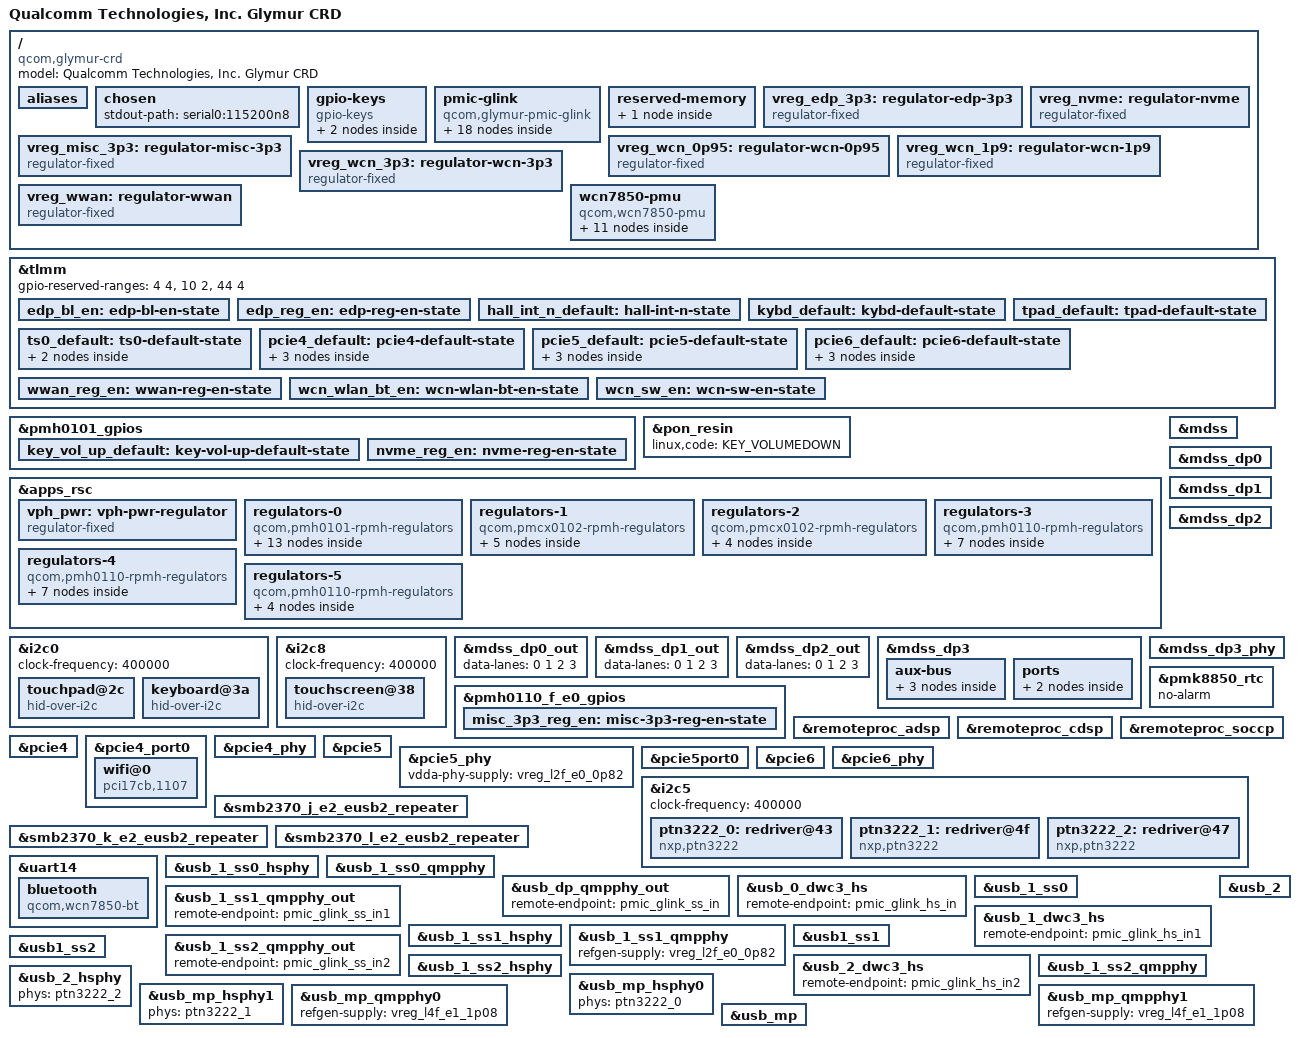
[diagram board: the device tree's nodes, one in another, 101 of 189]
// SPDX-License-Identifier: GPL-2.0-only
/*
 * Copyright (c) Qualcomm Technologies, Inc. and/or its subsidiaries.
 */

/dts-v1/;

#include "glymur.dtsi"
#include "glymur-pmics.dtsi"
#include <dt-bindings/gpio/gpio.h>
#include <dt-bindings/input/gpio-keys.h>
#include <dt-bindings/regulator/qcom,rpmh-regulator.h>
#include <dt-bindings/pinctrl/qcom,pmic-gpio.h>

/ {
	model = "Qualcomm Technologies, Inc. Glymur CRD";
	compatible = "qcom,glymur-crd", "qcom,glymur";

	aliases {
		serial0 = &uart21;
		serial1 = &uart14;
		i2c0 = &i2c16;
		i2c1 = &i2c17;
		i2c2 = &i2c18;
		i2c3 = &i2c19;
		i2c4 = &i2c20;
		i2c5 = &i2c22;
		i2c6 = &i2c23;
		i2c7 = &i2c8;
		i2c8 = &i2c9;
		i2c9 = &i2c10;
		i2c10 = &i2c11;
		i2c11 = &i2c12;
		i2c12 = &i2c13;
		i2c13 = &i2c15;
		i2c14 = &i2c0;
		i2c15 = &i2c1;
		i2c16 = &i2c2;
		i2c17 = &i2c3;
		i2c18 = &i2c4;
		i2c19 = &i2c5;
		i2c20 = &i2c6;
		spi0 = &spi16;
		spi1 = &spi17;
		spi2 = &spi18;
		spi3 = &spi19;
		spi4 = &spi20;
		spi5 = &spi22;
		spi6 = &spi23;
		spi7 = &spi8;
		spi8 = &spi9;
		spi9 = &spi10;
		spi10 = &spi11;
		spi11 = &spi12;
		spi12 = &spi13;
		spi13 = &spi15;
		spi14 = &spi0;
		spi15 = &spi1;
		spi16 = &spi2;
		spi17 = &spi3;
		spi18 = &spi4;
		spi19 = &spi5;
		spi20 = &spi6;
	};

	chosen {
		stdout-path = "serial0:115200n8";
	};

	gpio-keys {
		compatible = "gpio-keys";

		pinctrl-0 = <&key_vol_up_default>, <&hall_int_n_default>;
		pinctrl-names = "default";

		key-volume-up {
			label = "Volume Up";
			linux,code = <KEY_VOLUMEUP>;
			gpios = <&pmh0101_gpios 6 GPIO_ACTIVE_LOW>;
			debounce-interval = <15>;
			linux,can-disable;
			wakeup-source;
		};

		switch-lid {
			gpios = <&tlmm 92 GPIO_ACTIVE_LOW>;
			linux,input-type = <EV_SW>;
			linux,code = <SW_LID>;
			wakeup-source;
			wakeup-event-action = <EV_ACT_DEASSERTED>;
		};
	};

	pmic-glink {
		compatible = "qcom,glymur-pmic-glink";
		#address-cells = <1>;
		#size-cells = <0>;

		connector@0 {
			compatible = "usb-c-connector";
			reg = <0>;

			power-role = "dual";
			data-role = "dual";

			ports {
				#address-cells = <1>;
				#size-cells = <0>;

				port@0 {
					reg = <0>;

					pmic_glink_hs_in: endpoint {
						remote-endpoint = <&usb_0_dwc3_hs>;
					};
				};

				port@1 {
					reg = <1>;

					pmic_glink_ss_in: endpoint {
						remote-endpoint = <&usb_dp_qmpphy_out>;
					};
				};
			};
		};

		connector@1 {
			compatible = "usb-c-connector";
			reg = <1>;
			power-role = "dual";
			data-role = "dual";

			ports {
				#address-cells = <1>;
				#size-cells = <0>;

				port@0 {
					reg = <0>;

					pmic_glink_hs_in1: endpoint {
						remote-endpoint = <&usb_1_dwc3_hs>;
					};
				};

				port@1 {
					reg = <1>;

					pmic_glink_ss_in1: endpoint {
						remote-endpoint = <&usb_1_ss1_qmpphy_out>;
					};
				};
			};
		};

		connector@2 {
			compatible = "usb-c-connector";
			reg = <2>;
			power-role = "dual";
			data-role = "dual";

			ports {
				#address-cells = <1>;
				#size-cells = <0>;

				port@0 {
					reg = <0>;

					pmic_glink_hs_in2: endpoint {
						remote-endpoint = <&usb_2_dwc3_hs>;
					};
				};

				port@1 {
					reg = <1>;

					pmic_glink_ss_in2: endpoint {
						remote-endpoint = <&usb_1_ss2_qmpphy_out>;
					};
				};
			};
		};
	};

	reserved-memory {
		linux,cma {
			compatible = "shared-dma-pool";
			size = <0x0 0x8000000>;
			reusable;
			linux,cma-default;
		};
	};

	vreg_edp_3p3: regulator-edp-3p3 {
		compatible = "regulator-fixed";

		regulator-name = "VREG_EDP_3P3";
		regulator-min-microvolt = <3300000>;
		regulator-max-microvolt = <3300000>;

		gpio = <&tlmm 70 GPIO_ACTIVE_HIGH>;
		enable-active-high;

		pinctrl-0 = <&edp_reg_en>;
		pinctrl-names = "default";

		regulator-boot-on;
	};

	vreg_misc_3p3: regulator-misc-3p3 {
		compatible = "regulator-fixed";

		regulator-name = "VREG_MISC_3P3";
		regulator-min-microvolt = <3300000>;
		regulator-max-microvolt = <3300000>;

		gpio = <&pmh0110_f_e0_gpios 6 GPIO_ACTIVE_HIGH>;
		enable-active-high;

	        pinctrl-names = "default";
	        pinctrl-0 = <&misc_3p3_reg_en>;

		regulator-boot-on;
		regulator-always-on;
	};

	vreg_nvme: regulator-nvme {
		compatible = "regulator-fixed";

		regulator-name = "VREG_NVME_3P3";
		regulator-min-microvolt = <3300000>;
		regulator-max-microvolt = <3300000>;

		gpio = <&pmh0101_gpios 14 GPIO_ACTIVE_HIGH>;
		enable-active-high;

		pinctrl-0 = <&nvme_reg_en>;
		pinctrl-names = "default";
	};

	vreg_wcn_0p95: regulator-wcn-0p95 {
		compatible = "regulator-fixed";

		regulator-name = "VREG_WCN_0P95";
		regulator-min-microvolt = <950000>;
		regulator-max-microvolt = <950000>;

		vin-supply = <&vreg_wcn_3p3>;
	};

	vreg_wcn_1p9: regulator-wcn-1p9 {
		compatible = "regulator-fixed";

		regulator-name = "VREG_WCN_1P9";
		regulator-min-microvolt = <1900000>;
		regulator-max-microvolt = <1900000>;

		vin-supply = <&vreg_wcn_3p3>;
	};

	vreg_wcn_3p3: regulator-wcn-3p3 {
		compatible = "regulator-fixed";

		regulator-name = "VREG_WCN_3P3";
		regulator-min-microvolt = <3300000>;
		regulator-max-microvolt = <3300000>;

		gpio = <&tlmm 214 GPIO_ACTIVE_HIGH>;
		enable-active-high;

		pinctrl-0 = <&wcn_sw_en>;
		pinctrl-names = "default";

		regulator-boot-on;
	};

	vreg_wwan: regulator-wwan {
		compatible = "regulator-fixed";

		regulator-name = "VREG_WWAN_3P3";
		regulator-min-microvolt = <3300000>;
		regulator-max-microvolt = <3300000>;

		gpio = <&tlmm 246 GPIO_ACTIVE_HIGH>;
		enable-active-high;

		pinctrl-names = "default";
		pinctrl-0 = <&wwan_reg_en>;
	};

	wcn7850-pmu {
		compatible = "qcom,wcn7850-pmu";

		vdd-supply = <&vreg_wcn_0p95>;
		vddio-supply = <&vreg_l15b_e0_1p8>;
		vddaon-supply = <&vreg_wcn_0p95>;
		vdddig-supply = <&vreg_wcn_0p95>;
		vddrfa1p2-supply = <&vreg_wcn_1p9>;
		vddrfa1p8-supply = <&vreg_wcn_1p9>;

		wlan-enable-gpios = <&tlmm 117 GPIO_ACTIVE_HIGH>;
		bt-enable-gpios = <&tlmm 116 GPIO_ACTIVE_HIGH>;

		pinctrl-0 = <&wcn_wlan_bt_en>;
		pinctrl-names = "default";

		regulators {
			vreg_pmu_rfa_cmn: ldo0 {
				regulator-name = "vreg_pmu_rfa_cmn";
			};

			vreg_pmu_aon_0p59: ldo1 {
				regulator-name = "vreg_pmu_aon_0p59";
			};

			vreg_pmu_wlcx_0p8: ldo2 {
				regulator-name = "vreg_pmu_wlcx_0p8";
			};

			vreg_pmu_wlmx_0p85: ldo3 {
				regulator-name = "vreg_pmu_wlmx_0p85";
			};

			vreg_pmu_btcmx_0p85: ldo4 {
				regulator-name = "vreg_pmu_btcmx_0p85";
			};

			vreg_pmu_rfa_0p8: ldo5 {
				regulator-name = "vreg_pmu_rfa_0p8";
			};

			vreg_pmu_rfa_1p2: ldo6 {
				regulator-name = "vreg_pmu_rfa_1p2";
			};

			vreg_pmu_rfa_1p8: ldo7 {
				regulator-name = "vreg_pmu_rfa_1p8";
			};

			vreg_pmu_pcie_0p9: ldo8 {
				regulator-name = "vreg_pmu_pcie_0p9";
			};

			vreg_pmu_pcie_1p8: ldo9 {
				regulator-name = "vreg_pmu_pcie_1p8";
			};
		};
	};

};

&tlmm {
	gpio-reserved-ranges = <4 4>, <10 2>, <44 4>; /*Security SPI (TPM)*/

	edp_bl_en: edp-bl-en-state {
		pins = "gpio18";
		function = "gpio";
		drive-strength = <16>;
		bias-disable;
	};

	edp_reg_en: edp-reg-en-state {
		pins = "gpio70";
		function = "gpio";
		drive-strength = <16>;
		bias-disable;
	};

	hall_int_n_default: hall-int-n-state {
		pins = "gpio92";
		function = "gpio";
		bias-disable;
	};

	kybd_default: kybd-default-state {
		pins = "gpio67";
		function = "gpio";
		bias-disable;
	};

	tpad_default: tpad-default-state {
		pins = "gpio3";
		function = "gpio";
		bias-disable;
	};

	ts0_default: ts0-default-state {
		int-n-pins {
			pins = "gpio51";
			function = "gpio";
			bias-disable;
		};

		reset-n-pins {
			pins = "gpio48";
			function = "gpio";
			output-high;
			drive-strength = <16>;
		};
	};

	pcie4_default: pcie4-default-state {
		clkreq-n-pins {
			pins = "gpio147";
			function = "pcie4_clk_req_n";
			drive-strength = <2>;
			bias-pull-up;
		};

		perst-n-pins {
			pins = "gpio146";
			function = "gpio";
			drive-strength = <2>;
			bias-disable;
		};

		wake-n-pins {
			pins = "gpio148";
			function = "gpio";
			drive-strength = <2>;
			bias-pull-up;
		};
	};

	pcie5_default: pcie5-default-state {
		clkreq-n-pins {
			pins = "gpio153";
			function = "pcie5_clk_req_n";
			drive-strength = <2>;
			bias-pull-up;
		};

		perst-n-pins {
			pins = "gpio152";
			function = "gpio";
			drive-strength = <2>;
			bias-disable;
		};

		wake-n-pins {
			pins = "gpio154";
			function = "gpio";
			drive-strength = <2>;
			bias-pull-up;
		};
	};

	pcie6_default: pcie6-default-state {
		clkreq-n-pins {
			pins = "gpio150";
			function = "pcie6_clk_req_n";
			drive-strength = <2>;
			bias-pull-up;
		};

		perst-n-pins {
			pins = "gpio149";
			function = "gpio";
			drive-strength = <2>;
			bias-disable;
		};

		wake-n-pins {
			pins = "gpio151";
			function = "gpio";
			drive-strength = <2>;
			bias-pull-up;
		};
	};

	wwan_reg_en: wwan-reg-en-state {
		pins = "gpio246";
		function = "gpio";
		drive-strength = <2>;
		bias-disable;
	};

	wcn_wlan_bt_en: wcn-wlan-bt-en-state {
		pins = "gpio116", "gpio117";
		function = "gpio";
		drive-strength = <2>;
		bias-disable;
	};

	wcn_sw_en: wcn-sw-en-state {
		pins = "gpio214";
		function = "gpio";
		drive-strength = <2>;
		bias-disable;
	};
};

&pmh0101_gpios {
	key_vol_up_default: key-vol-up-default-state {
		pins = "gpio6";
		function = "gpio";
		output-disable;
		bias-pull-up;
	};
};

&pon_resin {
	linux,code = <KEY_VOLUMEDOWN>;
	status = "okay";
};

&apps_rsc {

	vph_pwr: vph-pwr-regulator {
		compatible = "regulator-fixed";
		regulator-name = "vph_pwr";
		regulator-min-microvolt = <3700000>;
		regulator-max-microvolt = <3700000>;
	};

	regulators-0 {
		compatible = "qcom,pmh0101-rpmh-regulators";
		qcom,pmic-id = "B_E0";

		vdd-bob1-supply = <&vph_pwr>;
		vdd-bob2-supply = <&vph_pwr>;
		vdd-l1-l10-l15-supply = <&vreg_s9f_e0_1p9>;
		vdd-l2-l7-l8-l9-l16-supply = <&vreg_bob1_e0>;
		vdd-l11-l12-l18-supply = <&vreg_s7f_e0_1p32>;
		vdd-l17-supply = <&vreg_bob2_e0>;

		vreg_bob1_e0: bob1 {
			regulator-name = "vreg_bob1_e0";
			regulator-min-microvolt = <2200000>;
			regulator-max-microvolt = <4224000>;
			regulator-initial-mode = <RPMH_REGULATOR_MODE_AUTO>;
		};

		vreg_bob2_e0: bob2 {
			regulator-name = "vreg_bob2_e0";
			regulator-min-microvolt = <2540000>;
			regulator-max-microvolt = <3600000>;
			regulator-initial-mode = <RPMH_REGULATOR_MODE_AUTO>;
		};

		vreg_l1b_e0_1p8: ldo1 {
			regulator-name = "vreg_l1b_e0_1p8";
			regulator-min-microvolt = <1800000>;
			regulator-max-microvolt = <1800000>;
			regulator-initial-mode = <RPMH_REGULATOR_MODE_HPM>;
		};

		vreg_l2b_e0_2p9: ldo2 {
			regulator-name = "vreg_l2b_e0_2p9";
			regulator-min-microvolt = <2900000>;
			regulator-max-microvolt = <3300000>;
			regulator-initial-mode = <RPMH_REGULATOR_MODE_HPM>;
		};

		vreg_l7b_e0_2p79: ldo7 {
			regulator-name = "vreg_l7b_e0_2p79";
			regulator-min-microvolt = <2790000>;
			regulator-max-microvolt = <3300000>;
			regulator-initial-mode = <RPMH_REGULATOR_MODE_HPM>;
		};

		vreg_l8b_e0_1p50: ldo8 {
			regulator-name = "vreg_l8b_e0_1p50";
			regulator-min-microvolt = <1504000>;
			regulator-max-microvolt = <3544000>;
			regulator-initial-mode = <RPMH_REGULATOR_MODE_HPM>;
		};

		vreg_l9b_e0_2p7: ldo9 {
			regulator-name = "vreg_l9b_e0_2p7";
			regulator-min-microvolt = <2700000>;
			regulator-max-microvolt = <3300000>;
			regulator-initial-mode = <RPMH_REGULATOR_MODE_HPM>;
		};

		vreg_l10b_e0_1p8: ldo10 {
			regulator-name = "vreg_l10b_e0_1p8";
			regulator-min-microvolt = <1800000>;
			regulator-max-microvolt = <1800000>;
			regulator-initial-mode = <RPMH_REGULATOR_MODE_HPM>;
		};

		vreg_l11b_e0_1p2: ldo11 {
			regulator-name = "vreg_l11b_e0_1p2";
			regulator-min-microvolt = <1200000>;
			regulator-max-microvolt = <1200000>;
			regulator-initial-mode = <RPMH_REGULATOR_MODE_HPM>;
		};

		vreg_l12b_e0_1p14: ldo12 {
			regulator-name = "vreg_l12b_e0_1p14";
			regulator-min-microvolt = <1140000>;
			regulator-max-microvolt = <1260000>;
			regulator-initial-mode = <RPMH_REGULATOR_MODE_HPM>;
		};

		vreg_l15b_e0_1p8: ldo15 {
			regulator-name = "vreg_l15b_e0_1p8";
			regulator-min-microvolt = <1800000>;
			regulator-max-microvolt = <1800000>;
			regulator-initial-mode = <RPMH_REGULATOR_MODE_HPM>;
		};

		vreg_l17b_e0_2p4: ldo17 {
			regulator-name = "vreg_l17b_e0_2p4";
			regulator-min-microvolt = <2400000>;
			regulator-max-microvolt = <2700000>;
			regulator-initial-mode = <RPMH_REGULATOR_MODE_HPM>;
		};

		vreg_l18b_e0_1p2: ldo18 {
			regulator-name = "vreg_l18b_e0_1p2";
			regulator-min-microvolt = <1200000>;
			regulator-max-microvolt = <1200000>;
			regulator-initial-mode = <RPMH_REGULATOR_MODE_HPM>;
		};
	};

	regulators-1 {
		compatible = "qcom,pmcx0102-rpmh-regulators";
		qcom,pmic-id = "C_E0";
		vdd-s1-supply = <&vph_pwr>;
		vdd-s8-supply = <&vph_pwr>;

		vreg_s1c_e0_0p3: smps1 {
			regulator-name = "vreg_s1c_e0_0p3";
			regulator-min-microvolt = <300000>;
			regulator-max-microvolt = <1200000>;
			regulator-initial-mode = <RPMH_REGULATOR_MODE_HPM>;
		};

		vreg_s8c_e0_0p3: smps8 {
			regulator-name = "vreg_s8c_e0_0p3";
			regulator-min-microvolt = <300000>;
			regulator-max-microvolt = <1200000>;
			regulator-initial-mode = <RPMH_REGULATOR_MODE_HPM>;
		};

		vreg_l2c_e0_0p72: ldo2 {
			regulator-name = "vreg_l2c_e0_0p72";
			regulator-min-microvolt = <720000>;
			regulator-max-microvolt = <950000>;
			regulator-initial-mode = <RPMH_REGULATOR_MODE_HPM>;
			regulator-allow-set-load;
				regulator-allowed-modes = <RPMH_REGULATOR_MODE_LPM
						   RPMH_REGULATOR_MODE_HPM>;
		};

		vreg_l4c_e0_1p2: ldo4 {
			regulator-name = "vreg_l4c_e0_1p2";
			regulator-min-microvolt = <1200000>;
			regulator-max-microvolt = <1200000>;
			regulator-initial-mode = <RPMH_REGULATOR_MODE_HPM>;
			regulator-allow-set-load;
			regulator-allowed-modes = <RPMH_REGULATOR_MODE_LPM
						   RPMH_REGULATOR_MODE_HPM>;
		};

		vreg_l1c_e0_0p89: ldo1 {
			regulator-name = "vreg_l1c_e0_0p89";
			regulator-min-microvolt = <890000>;
			regulator-max-microvolt = <980000>;
			regulator-initial-mode = <RPMH_REGULATOR_MODE_HPM>;
			regulator-allow-set-load;
			regulator-allowed-modes = <RPMH_REGULATOR_MODE_LPM
							RPMH_REGULATOR_MODE_HPM>;
		};
	};

	regulators-2 {
		compatible = "qcom,pmcx0102-rpmh-regulators";
		qcom,pmic-id = "C_E1";

		vdd-l2-supply = <&vreg_s7f_e0_1p32>;
		vdd-l1-l3-l4-supply = <&vreg_s8f_e0_0p95>;

		vreg_l1c_e1_0p82: ldo1 {
			regulator-name = "vreg_l1c_e1_0p82";
			regulator-min-microvolt = <825000>;
			regulator-max-microvolt = <958000>;
			regulator-initial-mode = <RPMH_REGULATOR_MODE_HPM>;
		};

		vreg_l2c_e1_1p14: ldo2 {
			regulator-name = "vreg_l2c_e1_1p14";
			regulator-min-microvolt = <1140000>;
			regulator-max-microvolt = <1300000>;
			regulator-initial-mode = <RPMH_REGULATOR_MODE_HPM>;
		};

		vreg_l3c_e1_0p89: ldo3 {
			regulator-name = "vreg_l3c_e1_0p89";
			regulator-min-microvolt = <890000>;
			regulator-max-microvolt = <980000>;
			regulator-initial-mode = <RPMH_REGULATOR_MODE_HPM>;
		};

		vreg_l4c_e1_0p72: ldo4 {
			regulator-name = "vreg_l4c_e1_0p72";
			regulator-min-microvolt = <720000>;
			regulator-max-microvolt = <980000>;
			regulator-initial-mode = <RPMH_REGULATOR_MODE_HPM>;
		};
	};

	regulators-3 {
		compatible = "qcom,pmh0110-rpmh-regulators";
		qcom,pmic-id = "F_E0";
		vdd-s7-supply = <&vph_pwr>;
		vdd-s8-supply = <&vph_pwr>;
		vdd-s9-supply = <&vph_pwr>;
		vdd-s10-supply = <&vph_pwr>;
		vdd-l2-supply = <&vreg_s8f_e0_0p95>;
		vdd-l3-supply = <&vreg_s8f_e0_0p95>;
		vdd-l4-supply = <&vreg_s8f_e0_0p95>;

		vreg_s7f_e0_1p32: smps7 {
			regulator-name = "vreg_s7f_e0_1p32";
			regulator-min-microvolt = <1320000>;
			regulator-max-microvolt = <1352000>;
			regulator-initial-mode = <RPMH_REGULATOR_MODE_HPM>;
		};

		vreg_s8f_e0_0p95: smps8 {
			regulator-name = "vreg_s8f_e0_0p95";
			regulator-min-microvolt = <952000>;
			regulator-max-microvolt = <1200000>;
			regulator-initial-mode = <RPMH_REGULATOR_MODE_HPM>;
		};

		vreg_s9f_e0_1p9: smps9 {
			regulator-name = "vreg_s9f_e0_1p9";
			regulator-min-microvolt = <1900000>;
			regulator-max-microvolt = <2000000>;
			regulator-initial-mode = <RPMH_REGULATOR_MODE_HPM>;
		};

		vreg_s10f_e0_0p3: smps10 {
			regulator-name = "vreg_s10f_e0_0p3";
			regulator-min-microvolt = <300000>;
			regulator-max-microvolt = <1200000>;
			regulator-initial-mode = <RPMH_REGULATOR_MODE_HPM>;
		};

		vreg_l2f_e0_0p82: ldo2 {
			regulator-name = "vreg_l2f_e0_0p82";
			regulator-min-microvolt = <825000>;
			regulator-max-microvolt = <980000>;
			regulator-initial-mode = <RPMH_REGULATOR_MODE_HPM>;
		};

		vreg_l3f_e0_0p72: ldo3 {
			regulator-name = "vreg_l3f_e0_0p72";
			regulator-min-microvolt = <720000>;
			regulator-max-microvolt = <980000>;
			regulator-initial-mode = <RPMH_REGULATOR_MODE_HPM>;
		};

		vreg_l4f_e0_0p3: ldo4 {
			regulator-name = "vreg_l4f_e0_0p3";
			regulator-min-microvolt = <300000>;
			regulator-max-microvolt = <1200000>;
			regulator-initial-mode = <RPMH_REGULATOR_MODE_HPM>;
		};
	};

	regulators-4 {
		compatible = "qcom,pmh0110-rpmh-regulators";
		qcom,pmic-id = "F_E1";
		vdd-s1-supply = <&vph_pwr>;
		vdd-s3-supply = <&vph_pwr>;
		vdd-s5-supply = <&vph_pwr>;
		vdd-s6-supply = <&vph_pwr>;
		vdd-s7-supply = <&vph_pwr>;
		vdd-l1-supply = <&vreg_s8f_e0_0p95>;
		vdd-l2-supply = <&vreg_s8f_e0_0p95>;
		vdd-l4-supply = <&vreg_s8f_e0_0p95>;

		vreg_s1f_e1_0p3: smps1 {
			regulator-name = "vreg_s1f_e1_0p3";
			regulator-min-microvolt = <300000>;
			regulator-max-microvolt = <1200000>;
			regulator-initial-mode = <RPMH_REGULATOR_MODE_HPM>;
		};

		vreg_s5f_e1_0p3: smps5 {
			regulator-name = "vreg_s5f_e1_0p3";
			regulator-min-microvolt = <300000>;
			regulator-max-microvolt = <1200000>;
			regulator-initial-mode = <RPMH_REGULATOR_MODE_HPM>;
		};

		vreg_s6f_e1_0p3: smps6 {
			regulator-name = "vreg_s6f_e1_0p3";
			regulator-min-microvolt = <300000>;
			regulator-max-microvolt = <1200000>;
			regulator-initial-mode = <RPMH_REGULATOR_MODE_HPM>;
		};

		vreg_s7f_e1_0p3: smps7 {
			regulator-name = "vreg_s7f_e1_0p3";
			regulator-min-microvolt = <300000>;
			regulator-max-microvolt = <1200000>;
			regulator-initial-mode = <RPMH_REGULATOR_MODE_HPM>;
		};

		vreg_l1f_e1_0p82: ldo1 {
			regulator-name = "vreg_l1f_e1_0p82";
			regulator-min-microvolt = <825000>;
			regulator-max-microvolt = <950000>;
			regulator-initial-mode = <RPMH_REGULATOR_MODE_HPM>;
		};

		vreg_l2f_e1_0p83: ldo2 {
			regulator-name = "vreg_l2f_e1_0p83";
			regulator-min-microvolt = <830000>;
			regulator-max-microvolt = <920000>;
			regulator-initial-mode = <RPMH_REGULATOR_MODE_HPM>;
		};

		vreg_l4f_e1_1p08: ldo4 {
			regulator-name = "vreg_l4f_e1_1p08";
			regulator-min-microvolt = <1080000>;
			regulator-max-microvolt = <1320000>;
			regulator-initial-mode = <RPMH_REGULATOR_MODE_HPM>;
		};
	};

	regulators-5 {
		compatible = "qcom,pmh0110-rpmh-regulators";
		qcom,pmic-id = "H_E0";

		vdd-l1-supply = <&vreg_s8f_e0_0p95>;
		vdd-l2-supply = <&vreg_s8f_e0_0p95>;
		vdd-l3-supply = <&vreg_s9f_e0_1p9>;
		vdd-l4-supply = <&vreg_s7f_e0_1p32>;

		vreg_l1h_e0_0p89: ldo1 {
			regulator-name = "vreg_l1h_e0_0p89";
			regulator-min-microvolt = <825000>;
			regulator-max-microvolt = <950000>;
			regulator-initial-mode = <RPMH_REGULATOR_MODE_HPM>;
		};

		vreg_l2h_e0_0p72: ldo2 {
			regulator-name = "vreg_l2h_e0_0p72";
			regulator-min-microvolt = <830000>;
			regulator-max-microvolt = <920000>;
			regulator-initial-mode = <RPMH_REGULATOR_MODE_HPM>;
		};

		vreg_l3h_e0_0p32: ldo3 {
			regulator-name = "vreg_l3h_e0_0p32";
			regulator-min-microvolt = <320000>;
			regulator-max-microvolt = <2000000>;
			regulator-initial-mode = <RPMH_REGULATOR_MODE_HPM>;
		};

		vreg_l4h_e0_1p2: ldo4 {
			regulator-name = "vreg_l4h_e0_1p2";
			regulator-min-microvolt = <1080000>;
			regulator-max-microvolt = <1320000>;
			regulator-initial-mode = <RPMH_REGULATOR_MODE_HPM>;
		};
	};
};

&i2c0 {
	clock-frequency = <400000>;

	status = "okay";

	touchpad@2c {
		compatible = "hid-over-i2c";
		reg = <0x2c>;

		hid-descr-addr = <0x20>;
		interrupts-extended = <&tlmm 3 IRQ_TYPE_LEVEL_LOW>;

		vdd-supply = <&vreg_misc_3p3>;
		vddl-supply = <&vreg_l15b_e0_1p8>;

		pinctrl-0 = <&tpad_default>;
		pinctrl-names = "default";

		wakeup-source;
	};

	keyboard@3a {
		compatible = "hid-over-i2c";
		reg = <0x3a>;

		hid-descr-addr = <0x1>;
		interrupts-extended = <&tlmm 67 IRQ_TYPE_LEVEL_LOW>;

		vdd-supply = <&vreg_misc_3p3>;
		vddl-supply = <&vreg_l15b_e0_1p8>;

		pinctrl-0 = <&kybd_default>;
		pinctrl-names = "default";

		wakeup-source;
	};
};

&i2c8 {
	clock-frequency = <400000>;

	status = "okay";

	touchscreen@38 {
		compatible = "hid-over-i2c";
		reg = <0x38>;

		hid-descr-addr = <0x1>;
		interrupts-extended = <&tlmm 51 IRQ_TYPE_LEVEL_LOW>;

		vdd-supply = <&vreg_misc_3p3>;
		vddl-supply = <&vreg_l15b_e0_1p8>;

		pinctrl-0 = <&ts0_default>;
		pinctrl-names = "default";
	};
};


&mdss {
	status = "okay";
};

&mdss_dp0 {
	status = "okay";
};

&mdss_dp0_out {
	data-lanes = <0 1 2 3>;
};

&mdss_dp1 {
	status = "okay";
};

&mdss_dp1_out {
	data-lanes = <0 1 2 3>;
};

&mdss_dp2 {
	status = "okay";
};

&mdss_dp2_out {
	data-lanes = <0 1 2 3>;
};

&mdss_dp3 {
	/delete-property/ #sound-dai-cells;

	status = "okay";

	aux-bus {
		panel {
			compatible = "samsung,atna60cl08", "samsung,atna33xc20";
			enable-gpios = <&tlmm 18 GPIO_ACTIVE_HIGH>;
			power-supply = <&vreg_edp_3p3>;

			pinctrl-0 = <&edp_bl_en>;
			pinctrl-names = "default";

			port {
				edp_panel_in: endpoint {
					remote-endpoint = <&mdss_dp3_out>;
				};
			};
		};
	};

	ports {
		port@1 {
			reg = <1>;
			mdss_dp3_out: endpoint {
				data-lanes = <0 1 2 3>;
				link-frequencies = /bits/ 64 <1620000000 2700000000 5400000000 8100000000>;

				remote-endpoint = <&edp_panel_in>;
			};
		};
	};
};

&mdss_dp3_phy {
	vdda-phy-supply = <&vreg_l2f_e1_0p83>;
	vdda-pll-supply = <&vreg_l4f_e1_1p08>;

	status = "okay";
};

&pmk8850_rtc {
	no-alarm;
};

&pmh0101_gpios {
	nvme_reg_en: nvme-reg-en-state {
		pins = "gpio14";
		function = "normal";
		bias-disable;
	};
};

&pmh0110_f_e0_gpios {
	misc_3p3_reg_en: misc-3p3-reg-en-state {
		pins = "gpio6";
		function = "normal";
		bias-disable;
		input-disable;
		output-enable;
		drive-push-pull;
		power-source = <1>; /* 1.8 V */
		qcom,drive-strength = <PMIC_GPIO_STRENGTH_LOW>;
	};
};

&remoteproc_adsp {
	firmware-name = "qcom/glymur/adsp.mbn",
			"qcom/glymur/adsp_dtb.mbn";

	status = "okay";
};

&remoteproc_cdsp {
	firmware-name = "qcom/glymur/cdsp.mbn",
			"qcom/glymur/cdsp_dtb.mbn";

	status = "okay";
};

&remoteproc_soccp {
	firmware-name = "qcom/glymur/soccp.mbn",
			"qcom/glymur/soccp_dtb.mbn";

	status = "okay";
};

&pcie4 {
	perst-gpios = <&tlmm 146 GPIO_ACTIVE_LOW>;
	wake-gpios = <&tlmm 148 GPIO_ACTIVE_LOW>;

	pinctrl-0 = <&pcie4_default>;
	pinctrl-names = "default";

	status = "ok";
};

&pcie4_port0 {
	wifi@0 {
		compatible = "pci17cb,1107";
		reg = <0x10000 0x0 0x0 0x0 0x0>;

		vddaon-supply = <&vreg_pmu_aon_0p59>;
		vddwlcx-supply = <&vreg_pmu_wlcx_0p8>;
		vddwlmx-supply = <&vreg_pmu_wlmx_0p85>;
		vddrfacmn-supply = <&vreg_pmu_rfa_cmn>;
		vddrfa0p8-supply = <&vreg_pmu_rfa_0p8>;
		vddrfa1p2-supply = <&vreg_pmu_rfa_1p2>;
		vddrfa1p8-supply = <&vreg_pmu_rfa_1p8>;
		vddpcie0p9-supply = <&vreg_pmu_pcie_0p9>;
		vddpcie1p8-supply = <&vreg_pmu_pcie_1p8>;
	};
};

&pcie4_phy {
	vdda-phy-supply = <&vreg_l1c_e1_0p82>;
	vdda-pll-supply = <&vreg_l4f_e1_1p08>;
	vdda-qref-supply = <&vreg_l2f_e1_0p83>;
	vdda-refgen-supply = <&vreg_l1f_e1_0p82>;

	status = "ok";
};

&pcie5 {
	vddpe-3v3-supply = <&vreg_nvme>;

	pinctrl-0 = <&pcie5_default>;
	pinctrl-names = "default";

	status = "okay";
};

&pcie5_phy {
	vdda-phy-supply = <&vreg_l2f_e0_0p82>;
//	vdda-pll-supply = <&vreg_l4h_e0_1p2>;

	status = "okay";
};

&pcie5port0 {
	perst-gpios = <&tlmm 152 GPIO_ACTIVE_LOW>;
	wake-gpios = <&tlmm 154 GPIO_ACTIVE_LOW>;
};

&pcie6 {
	vddpe-3v3-supply = <&vreg_wwan>;

	perst-gpios = <&tlmm 149 GPIO_ACTIVE_LOW>;
	wake-gpios = <&tlmm 151 GPIO_ACTIVE_LOW>;

	pinctrl-0 = <&pcie6_default>;
	pinctrl-names = "default";

	status = "ok";
};

&pcie6_phy {
	vdda-phy-supply = <&vreg_l1c_e1_0p82>;
	vdda-pll-supply = <&vreg_l4f_e1_1p08>;
	vdda-qref-supply = <&vreg_l2f_e1_0p83>;
	vdda-refgen-supply = <&vreg_l1f_e1_0p82>;

	status = "ok";
};

&i2c5 {
	status = "ok";

	clock-frequency = <400000>;

	ptn3222_0: redriver@43 {
		compatible = "nxp,ptn3222";
		reg = <0x43>;

		reset-gpios = <&tlmm 8 GPIO_ACTIVE_LOW>;

		vdd3v3-supply = <&vreg_l8b_e0_1p50>;
		vdd1v8-supply = <&vreg_l15b_e0_1p8>;

		#phy-cells = <0>;
	};

	ptn3222_1: redriver@4f {
		compatible = "nxp,ptn3222";
		reg = <0x4f>;

		reset-gpios = <&tlmm 184 GPIO_ACTIVE_LOW>;

		vdd3v3-supply = <&vreg_l8b_e0_1p50>;
		vdd1v8-supply = <&vreg_l15b_e0_1p8>;

		#phy-cells = <0>;
	};

	ptn3222_2: redriver@47 {
		compatible = "nxp,ptn3222";
		reg = <0x47>;

		reset-gpios = <&tlmm 9 GPIO_ACTIVE_LOW>;

		vdd3v3-supply = <&vreg_l8b_e0_1p50>;
		vdd1v8-supply = <&vreg_l15b_e0_1p8>;

		#phy-cells = <0>;
	};
};

&smb2370_j_e2_eusb2_repeater {
	vdd18-supply = <&vreg_l15b_e0_1p8>;
	vdd3-supply = <&vreg_l7b_e0_2p79>;
};

&smb2370_k_e2_eusb2_repeater {
	vdd18-supply = <&vreg_l15b_e0_1p8>;
	vdd3-supply = <&vreg_l7b_e0_2p79>;
};

&smb2370_l_e2_eusb2_repeater {
	vdd18-supply = <&vreg_l15b_e0_1p8>;
	vdd3-supply = <&vreg_l7b_e0_2p79>;
};

&uart14 {
	status = "okay";

	bluetooth {
		compatible = "qcom,wcn7850-bt";
		max-speed = <3200000>;

		vddaon-supply = <&vreg_pmu_aon_0p59>;
		vddwlcx-supply = <&vreg_pmu_wlcx_0p8>;
		vddwlmx-supply = <&vreg_pmu_wlmx_0p85>;
		vddrfacmn-supply = <&vreg_pmu_rfa_cmn>;
		vddrfa0p8-supply = <&vreg_pmu_rfa_0p8>;
		vddrfa1p2-supply = <&vreg_pmu_rfa_1p2>;
		vddrfa1p8-supply = <&vreg_pmu_rfa_1p8>;
	};
};

&usb_1_ss0_hsphy {
	vdd-supply = <&vreg_l3f_e0_0p72>;

	phys = <&smb2370_j_e2_eusb2_repeater>;

	status = "okay";
};

&usb_1_ss0_qmpphy {
	vdda-pll-supply = <&vreg_l3f_e0_0p72>;
	refgen-supply = <&vreg_l2f_e0_0p82>;

	status = "okay";
};

&usb_dp_qmpphy_out {
	remote-endpoint = <&pmic_glink_ss_in>;
};

&usb_0_dwc3_hs {
	remote-endpoint = <&pmic_glink_hs_in>;
};

&usb_1_ss0 {
	dr_mode = "otg";
	usb-role-switch;

	status = "okay";
};

&usb_1_ss1_qmpphy_out {
	remote-endpoint = <&pmic_glink_ss_in1>;
};

&usb_1_dwc3_hs {
	remote-endpoint = <&pmic_glink_hs_in1>;
};

&usb_1_ss1_hsphy {
	vdd-supply = <&vreg_l3f_e0_0p72>;

	phys = <&smb2370_k_e2_eusb2_repeater>;

	status = "okay";
};

&usb_1_ss1_qmpphy {
	refgen-supply = <&vreg_l2f_e0_0p82>;

	status = "okay";
};

&usb1_ss1 {
	dr_mode = "otg";
	usb-role-switch;

	status = "okay";
};

&usb_1_ss2_qmpphy_out {
	remote-endpoint = <&pmic_glink_ss_in2>;
};

&usb_2_dwc3_hs {
	remote-endpoint = <&pmic_glink_hs_in2>;
};

&usb_1_ss2_hsphy {
	vdd-supply = <&vreg_l4c_e1_0p72>;
	vdda12-supply = <&vreg_l4f_e1_1p08>;

	phys = <&smb2370_l_e2_eusb2_repeater>;

	status = "okay";
};

&usb_1_ss2_qmpphy {
	vdda-phy-supply = <&vreg_l4f_e1_1p08>;
	vdda-pll-supply = <&vreg_l4c_e1_0p72>;
	refgen-supply = <&vreg_l1c_e1_0p82>;

	status = "okay";
};

&usb1_ss2 {
	dr_mode = "otg";
	usb-role-switch;

	status = "okay";
};

&usb_2 {
	status = "okay";
};

&usb_2_hsphy {
	phys = <&ptn3222_2>;

	status = "okay";
};

&usb_mp_hsphy0 {
	phys = <&ptn3222_0>;

	status = "okay";
};

&usb_mp_hsphy1 {
	phys = <&ptn3222_1>;

	status = "okay";
};

&usb_mp_qmpphy0 {
	refgen-supply = <&vreg_l4f_e1_1p08>;

	status = "okay";
};

&usb_mp_qmpphy1 {
	refgen-supply = <&vreg_l4f_e1_1p08>;

	status = "okay";
};

&usb_mp {
	status = "okay";
};
